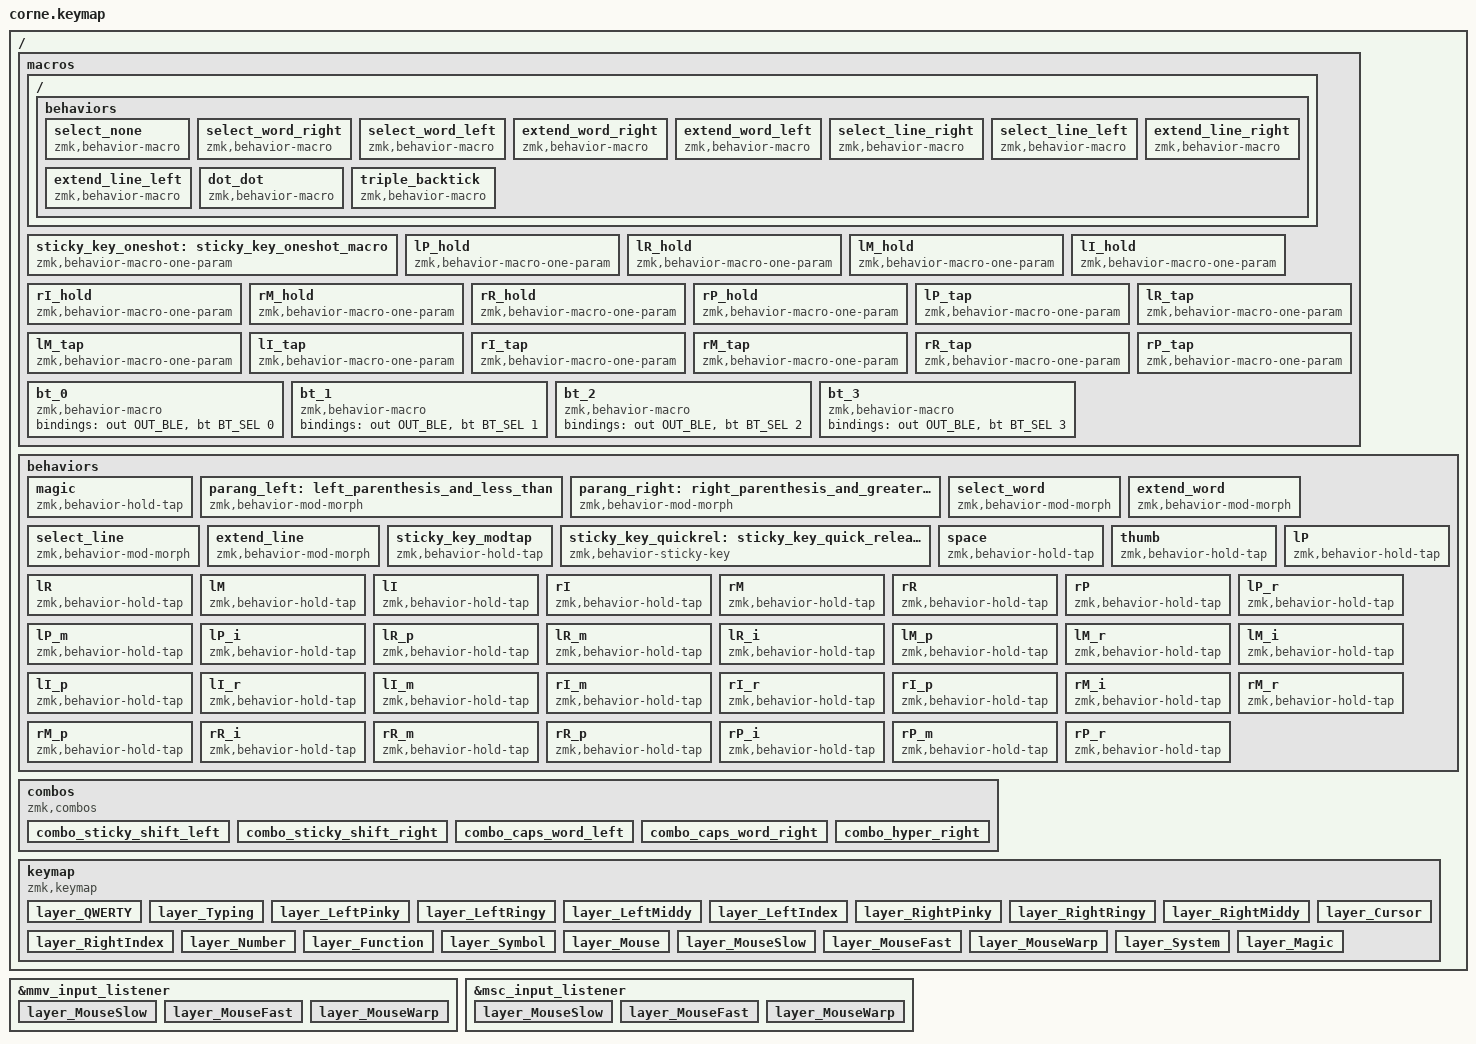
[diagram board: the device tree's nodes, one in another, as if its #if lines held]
/*
 * Copyright (c) 2020 The ZMK Contributors
 * Corne 3x6+3 keymap adapted from MoErgo Go60 with bilateral HRM
 * SPDX-License-Identifier: MIT
 */

#include <behaviors.dtsi>
#include <dt-bindings/zmk/outputs.h>
#include <dt-bindings/zmk/keys.h>
#include <dt-bindings/zmk/bt.h>
#include <dt-bindings/zmk/pointing.h>
#include <input/processors.dtsi>

/* ── Helper macros ── */

/* ZMK_MACRO() comes from <behaviors.dtsi> (app/dts/behaviors/macros.dtsi). */

/* ── sunaku timing constants (keymap.zmk:1724, 3954, 3962, 4091) ── */

#define TAPPING_RESOLUTION  150
#define STICKY_HOLDING_TIME (TAPPING_RESOLUTION + 50)
#define STICKY_1SHOT_DECAY  500
#define SELECT_WORD_DELAY   1

/* ── Operating system ──
 *
 * Verbatim from sunaku's Glorious Engrammer v52 (keymap.zmk:925-967), pinned to
 * macOS. Copied rather than hand-translated so the shortcuts match the Glove80.
 */

#define OPERATING_SYSTEM 'M' // macos

#if OPERATING_SYSTEM == 'M'
  #define _C      LG
  #define _A_TAB  LGUI
  #define _G_TAB  LALT
  #define _REDO   LG(LS(Z))
  #define _POWER  K_POWER
  #define _WORD   LA
  #define _HOME   LG(LEFT)
  #define _END    LG(RIGHT)
  #define _FILES  LG(LA(SPACE))
  #define _GLOBE  GLOBE
#else
  #define _C      LC
  #define _A_TAB  LALT
  #define _G_TAB  LGUI
  #define _REDO   LC(Y)
  #define _POWER  C_POWER
  #define _WORD   LC
  #define _HOME   HOME
  #define _END    END
  #define _FILES  LG(E)
  #define _GLOBE  LGUI
#endif
#define _SLEEP      C_SLEEP
#if OPERATING_SYSTEM == 'M'
  #define _LOCK   _C(LC(Q))
#else
  #define _LOCK   K_LOCK
#endif
#define _UNDO       _C(Z)
#define _CUT        _C(X)
#define _COPY       _C(C)
#define _PASTE      _C(V)
#define _FIND       _C(F)
#define _FIND_NEXT  _C(G)
#define _FIND_PREV  _C(LS(G))

#if OPERATING_SYSTEM == 'M'
  #define _SNAP   LG(LS(N5))  /* macOS screenshot toolbar (Cmd+Shift+5) */
#else
  #define _SNAP   PSCRN
#endif

/* keymap.zmk:4093 -- not a node; expands at the &-site into &kp _C(A) */
#define select_all kp _C(A)

/* ── Layer IDs ──
 *
 * sunaku's 32-layer Glove80 keymap minus what a Corne cannot use: the three alt
 * alpha layouts, Gaming (Glove80 keywell geometry), Emoji/World (reached only
 * from the lost R6), Factory (Glove80-specific), and the macOS toggle layers
 * (macOS is baked into the base instead — see OPERATING_SYSTEM above).
 *
 * 21 of ZMK's 32 slots. Home-row mods relaxed to non-bilateral (see HRM triggers).
 */

#define LAYER_QWERTY 0
#define LAYER_Typing 1
#define LAYER_LeftPinky 2
#define LAYER_LeftRingy 3
#define LAYER_LeftMiddy 4
#define LAYER_LeftIndex 5
#define LAYER_RightPinky 6
#define LAYER_RightRingy 7
#define LAYER_RightMiddy 8
#define LAYER_RightIndex 9
#define LAYER_Cursor 10
#define LAYER_Number 11
#define LAYER_Function 12
#define LAYER_Symbol 13
#define LAYER_Mouse 14
#define LAYER_MouseSlow 15
#define LAYER_MouseFast 16
#define LAYER_MouseWarp 17
#define LAYER_System 18
#define LAYER_Magic 19

/* ── HRM trigger positions (non-bilateral) ── */

/* NON-BILATERAL (full relax): every key position triggers the hold, so home-row
 * mods fire on the SAME hand too -- e.g. one-handed Cmd+T. This drops sunaku's
 * bilateral typing protection by choice; the tap-preferred flavor + the
 * require-prior-idle-ms guards below still gate a mod behind a deliberate ~0.2s
 * hold after a brief pause, which is how you start a shortcut but not how you
 * type mid-word. If fast same-hand typing misfires a mod (Shift on the index,
 * require-prior-idle-ms=25, is likeliest), raise that idle guard. To restore
 * bilateral, set LEFT back to the right-hand positions and RIGHT to the left.
 */
#define LEFT_HRM_TRIGGERS \
    0 1 2 3 4 5 6 7 8 9 10 11 \
    12 13 14 15 16 17 18 19 20 21 22 23 \
    24 25 26 27 28 29 30 31 32 33 34 35 \
    36 37 38 39 40 41

#define RIGHT_HRM_TRIGGERS \
    0 1 2 3 4 5 6 7 8 9 10 11 \
    12 13 14 15 16 17 18 19 20 21 22 23 \
    24 25 26 27 28 29 30 31 32 33 34 35 \
    36 37 38 39 40 41

/* ── System behaviors ── */

/* No &led_strip override: this Corne has no LEDs installed. See build.yaml. */

&mmv_input_listener {
    layer_MouseSlow {
        layers = <LAYER_MouseSlow>;
        input-processors = <&zip_xy_scaler 1 9>;
    };
    layer_MouseFast {
        layers = <LAYER_MouseFast>;
        input-processors = <&zip_xy_scaler 3 1>;
    };
    layer_MouseWarp {
        layers = <LAYER_MouseWarp>;
        input-processors = <&zip_xy_scaler 12 1>;
    };
};

&msc_input_listener {
    layer_MouseSlow {
        layers = <LAYER_MouseSlow>;
        input-processors = <&zip_scroll_scaler 1 9>;
    };
    layer_MouseFast {
        layers = <LAYER_MouseFast>;
        input-processors = <&zip_scroll_scaler 3 1>;
    };
    layer_MouseWarp {
        layers = <LAYER_MouseWarp>;
        input-processors = <&zip_scroll_scaler 12 1>;
    };
};

/* No conditional layers. erickueen's ThumbShift layer (Cursor+Symbol -> shifted
 * alphas) is not part of sunaku's design and is dropped along with its layer.
 */

/* ── Macros ── */

/ {
    macros {

        /* ── Ported from sunaku's Glorious Engrammer v52 ──
         *
         * select/extend family: keymap.zmk:4093-4180. Each is a mod-morph pair so
         * that holding Shift selects/extends leftward instead of rightward. The
         * _WORD/_HOME/_END tokens resolve per OPERATING_SYSTEM (see top of file).
         */

        ZMK_MACRO(select_none,
            wait-ms = <SELECT_WORD_DELAY>;
            tap-ms = <SELECT_WORD_DELAY>;
            bindings = <&kp DOWN &kp UP &kp RIGHT &kp LEFT>;
        )

        ZMK_MACRO(select_word_right,
            wait-ms = <SELECT_WORD_DELAY>;
            tap-ms = <SELECT_WORD_DELAY>;
            bindings = <&kp _WORD(RIGHT) &kp _WORD(LEFT) &kp _WORD(LS(RIGHT))>;
        )
        ZMK_MACRO(select_word_left,
            wait-ms = <SELECT_WORD_DELAY>;
            tap-ms = <SELECT_WORD_DELAY>;
            bindings = <&kp _WORD(LEFT) &kp _WORD(RIGHT) &kp _WORD(LS(LEFT))>;
        )

        ZMK_MACRO(extend_word_right,
            wait-ms = <SELECT_WORD_DELAY>;
            tap-ms = <SELECT_WORD_DELAY>;
            bindings = <&kp _WORD(LS(RIGHT))>;
        )
        ZMK_MACRO(extend_word_left,
            wait-ms = <SELECT_WORD_DELAY>;
            tap-ms = <SELECT_WORD_DELAY>;
            bindings = <&kp _WORD(LS(LEFT))>;
        )

        ZMK_MACRO(select_line_right,
            wait-ms = <SELECT_WORD_DELAY>;
            tap-ms = <SELECT_WORD_DELAY>;
            bindings = <&kp _HOME &kp LS(_END)>;
        )
        ZMK_MACRO(select_line_left,
            wait-ms = <SELECT_WORD_DELAY>;
            tap-ms = <SELECT_WORD_DELAY>;
            bindings = <&kp _END &kp LS(_HOME)>;
        )

        ZMK_MACRO(extend_line_right,
            wait-ms = <SELECT_WORD_DELAY>;
            tap-ms = <SELECT_WORD_DELAY>;
            bindings = <&kp LS(DOWN) &kp LS(_END)>;
        )
        ZMK_MACRO(extend_line_left,
            wait-ms = <SELECT_WORD_DELAY>;
            tap-ms = <SELECT_WORD_DELAY>;
            bindings = <&kp LS(UP) &kp LS(_HOME)>;
        )

        /* keymap.zmk:4014-4024 */
        ZMK_MACRO(dot_dot,
            wait-ms = <0>;
            tap-ms = <0>;
            bindings = <&macro_tap &kp DOT &kp DOT>;
        )
        ZMK_MACRO(triple_backtick,
            wait-ms = <0>;
            tap-ms = <0>;
            bindings = <&macro_tap &kp GRAVE &kp GRAVE &kp GRAVE>;
        )

        /* keymap.zmk:3972-3981 */
        sticky_key_oneshot: sticky_key_oneshot_macro {
            compatible = "zmk,behavior-macro-one-param";
            wait-ms = <0>;
            tap-ms = <0>;
            #binding-cells = <1>;
            bindings
              = <&macro_param_1to1>
              , <&macro_tap &sticky_key_quickrel MACRO_PLACEHOLDER>
              ;
        };









        /* Bilateral HRM hold macros — press modifier + activate layer */

        lP_hold: lP_hold {
            compatible = "zmk,behavior-macro-one-param";
            #binding-cells = <1>;
            tap-ms = <0>; wait-ms = <0>;
            bindings = <&macro_press>
                , <&macro_param_1to1>, <&kp A>
                , <&mo LAYER_LeftPinky>
                , <&macro_pause_for_release>
                , <&macro_release>
                , <&macro_param_1to1>, <&kp A>
                , <&mo LAYER_LeftPinky>;
        };
        lR_hold: lR_hold {
            compatible = "zmk,behavior-macro-one-param";
            #binding-cells = <1>;
            tap-ms = <0>; wait-ms = <0>;
            bindings = <&macro_press>
                , <&macro_param_1to1>, <&kp A>
                , <&mo LAYER_LeftRingy>
                , <&macro_pause_for_release>
                , <&macro_release>
                , <&macro_param_1to1>, <&kp A>
                , <&mo LAYER_LeftRingy>;
        };
        lM_hold: lM_hold {
            compatible = "zmk,behavior-macro-one-param";
            #binding-cells = <1>;
            tap-ms = <0>; wait-ms = <0>;
            bindings = <&macro_press>
                , <&macro_param_1to1>, <&kp A>
                , <&mo LAYER_LeftMiddy>
                , <&macro_pause_for_release>
                , <&macro_release>
                , <&macro_param_1to1>, <&kp A>
                , <&mo LAYER_LeftMiddy>;
        };
        lI_hold: lI_hold {
            compatible = "zmk,behavior-macro-one-param";
            #binding-cells = <1>;
            tap-ms = <0>; wait-ms = <0>;
            bindings = <&macro_press>
                , <&macro_param_1to1>, <&kp A>
                , <&mo LAYER_LeftIndex>
                , <&macro_pause_for_release>
                , <&macro_release>
                , <&macro_param_1to1>, <&kp A>
                , <&mo LAYER_LeftIndex>;
        };
        rI_hold: rI_hold {
            compatible = "zmk,behavior-macro-one-param";
            #binding-cells = <1>;
            tap-ms = <0>; wait-ms = <0>;
            bindings = <&macro_press>
                , <&macro_param_1to1>, <&kp A>
                , <&mo LAYER_RightIndex>
                , <&macro_pause_for_release>
                , <&macro_release>
                , <&macro_param_1to1>, <&kp A>
                , <&mo LAYER_RightIndex>;
        };
        rM_hold: rM_hold {
            compatible = "zmk,behavior-macro-one-param";
            #binding-cells = <1>;
            tap-ms = <0>; wait-ms = <0>;
            bindings = <&macro_press>
                , <&macro_param_1to1>, <&kp A>
                , <&mo LAYER_RightMiddy>
                , <&macro_pause_for_release>
                , <&macro_release>
                , <&macro_param_1to1>, <&kp A>
                , <&mo LAYER_RightMiddy>;
        };
        rR_hold: rR_hold {
            compatible = "zmk,behavior-macro-one-param";
            #binding-cells = <1>;
            tap-ms = <0>; wait-ms = <0>;
            bindings = <&macro_press>
                , <&macro_param_1to1>, <&kp A>
                , <&mo LAYER_RightRingy>
                , <&macro_pause_for_release>
                , <&macro_release>
                , <&macro_param_1to1>, <&kp A>
                , <&mo LAYER_RightRingy>;
        };
        rP_hold: rP_hold {
            compatible = "zmk,behavior-macro-one-param";
            #binding-cells = <1>;
            tap-ms = <0>; wait-ms = <0>;
            bindings = <&macro_press>
                , <&macro_param_1to1>, <&kp A>
                , <&mo LAYER_RightPinky>
                , <&macro_pause_for_release>
                , <&macro_release>
                , <&macro_param_1to1>, <&kp A>
                , <&mo LAYER_RightPinky>;
        };

        /* Bilateral HRM tap macros — release all mods, tap held key, tap param key */

        lP_tap: lP_tap {
            compatible = "zmk,behavior-macro-one-param";
            #binding-cells = <1>;
            tap-ms = <0>; wait-ms = <0>;
            bindings = <&macro_release>
                , <&kp LSHFT>, <&kp RSHFT>, <&kp LALT>, <&kp RALT>
                , <&kp LCTRL>, <&kp RCTRL>, <&kp LGUI>, <&kp RGUI>
                , <&macro_tap>, <&kp A>
                , <&macro_tap>, <&macro_param_1to1>, <&kp A>;
        };
        lR_tap: lR_tap {
            compatible = "zmk,behavior-macro-one-param";
            #binding-cells = <1>;
            tap-ms = <0>; wait-ms = <0>;
            bindings = <&macro_release>
                , <&kp LSHFT>, <&kp RSHFT>, <&kp LALT>, <&kp RALT>
                , <&kp LCTRL>, <&kp RCTRL>, <&kp LGUI>, <&kp RGUI>
                , <&macro_tap>, <&kp S>
                , <&macro_tap>, <&macro_param_1to1>, <&kp A>;
        };
        lM_tap: lM_tap {
            compatible = "zmk,behavior-macro-one-param";
            #binding-cells = <1>;
            tap-ms = <0>; wait-ms = <0>;
            bindings = <&macro_release>
                , <&kp LSHFT>, <&kp RSHFT>, <&kp LALT>, <&kp RALT>
                , <&kp LCTRL>, <&kp RCTRL>, <&kp LGUI>, <&kp RGUI>
                , <&macro_tap>, <&kp D>
                , <&macro_tap>, <&macro_param_1to1>, <&kp A>;
        };
        lI_tap: lI_tap {
            compatible = "zmk,behavior-macro-one-param";
            #binding-cells = <1>;
            tap-ms = <0>; wait-ms = <0>;
            bindings = <&macro_release>
                , <&kp LSHFT>, <&kp RSHFT>, <&kp LALT>, <&kp RALT>
                , <&kp LCTRL>, <&kp RCTRL>, <&kp LGUI>, <&kp RGUI>
                , <&macro_tap>, <&kp F>
                , <&macro_tap>, <&macro_param_1to1>, <&kp A>;
        };
        rI_tap: rI_tap {
            compatible = "zmk,behavior-macro-one-param";
            #binding-cells = <1>;
            tap-ms = <0>; wait-ms = <0>;
            bindings = <&macro_release>
                , <&kp LSHFT>, <&kp RSHFT>, <&kp LALT>, <&kp RALT>
                , <&kp LCTRL>, <&kp RCTRL>, <&kp LGUI>, <&kp RGUI>
                , <&macro_tap>, <&kp J>
                , <&macro_tap>, <&macro_param_1to1>, <&kp A>;
        };
        rM_tap: rM_tap {
            compatible = "zmk,behavior-macro-one-param";
            #binding-cells = <1>;
            tap-ms = <0>; wait-ms = <0>;
            bindings = <&macro_release>
                , <&kp LSHFT>, <&kp RSHFT>, <&kp LALT>, <&kp RALT>
                , <&kp LCTRL>, <&kp RCTRL>, <&kp LGUI>, <&kp RGUI>
                , <&macro_tap>, <&kp K>
                , <&macro_tap>, <&macro_param_1to1>, <&kp A>;
        };
        rR_tap: rR_tap {
            compatible = "zmk,behavior-macro-one-param";
            #binding-cells = <1>;
            tap-ms = <0>; wait-ms = <0>;
            bindings = <&macro_release>
                , <&kp LSHFT>, <&kp RSHFT>, <&kp LALT>, <&kp RALT>
                , <&kp LCTRL>, <&kp RCTRL>, <&kp LGUI>, <&kp RGUI>
                , <&macro_tap>, <&kp L>
                , <&macro_tap>, <&macro_param_1to1>, <&kp A>;
        };
        rP_tap: rP_tap {
            compatible = "zmk,behavior-macro-one-param";
            #binding-cells = <1>;
            tap-ms = <0>; wait-ms = <0>;
            bindings = <&macro_release>
                , <&kp LSHFT>, <&kp RSHFT>, <&kp LALT>, <&kp RALT>
                , <&kp LCTRL>, <&kp RCTRL>, <&kp LGUI>, <&kp RGUI>
                , <&macro_tap>, <&kp SEMI>
                , <&macro_tap>, <&macro_param_1to1>, <&kp A>;
        };

        /* Bluetooth macros */

        bt_0: bt_0 { compatible = "zmk,behavior-macro"; #binding-cells = <0>;
            bindings = <&out OUT_BLE>, <&bt BT_SEL 0>; };
        bt_1: bt_1 { compatible = "zmk,behavior-macro"; #binding-cells = <0>;
            bindings = <&out OUT_BLE>, <&bt BT_SEL 1>; };
        bt_2: bt_2 { compatible = "zmk,behavior-macro"; #binding-cells = <0>;
            bindings = <&out OUT_BLE>, <&bt BT_SEL 2>; };
        bt_3: bt_3 { compatible = "zmk,behavior-macro"; #binding-cells = <0>;
            bindings = <&out OUT_BLE>, <&bt BT_SEL 3>; };


    };
};

/* ── Behaviors ── */

/ {
    behaviors {

        /* sunaku taps Magic to flash RGB battery/BT status. With no LEDs there is
         * nothing to show, so the tap is a no-op and only the hold is used.
         */
        magic: magic {
            compatible = "zmk,behavior-hold-tap";
            #binding-cells = <2>;
            flavor = "tap-preferred";
            tapping-term-ms = <200>;
            bindings = <&mo>, <&none>;
        };

        /* ── Ported from sunaku's Glorious Engrammer v52 ── */

        /* keymap.zmk:3926-3941. Shift morphs ( ) into < > */
        parang_left: left_parenthesis_and_less_than {
            compatible = "zmk,behavior-mod-morph";
            #binding-cells = <0>;
            bindings = <&kp LPAR>, <&kp LT>;
            mods = <(MOD_LSFT|MOD_RSFT)>;
        };
        parang_right: right_parenthesis_and_greater_than {
            compatible = "zmk,behavior-mod-morph";
            #binding-cells = <0>;
            bindings = <&kp RPAR>, <&kp GT>;
            mods = <(MOD_LSFT|MOD_RSFT)>;
        };

        /* keymap.zmk:4105-4180. Shift selects/extends leftward. */
        select_word: select_word {
            compatible = "zmk,behavior-mod-morph";
            #binding-cells = <0>;
            bindings = <&select_word_right>, <&select_word_left>;
            mods = <(MOD_LSFT|MOD_RSFT)>;
        };
        extend_word: extend_word {
            compatible = "zmk,behavior-mod-morph";
            #binding-cells = <0>;
            bindings = <&extend_word_right>, <&extend_word_left>;
            mods = <(MOD_LSFT|MOD_RSFT)>;
        };
        select_line: select_line {
            compatible = "zmk,behavior-mod-morph";
            #binding-cells = <0>;
            bindings = <&select_line_right>, <&select_line_left>;
            mods = <(MOD_LSFT|MOD_RSFT)>;
        };
        extend_line: extend_line {
            compatible = "zmk,behavior-mod-morph";
            #binding-cells = <0>;
            bindings = <&extend_line_right>, <&extend_line_left>;
            mods = <(MOD_LSFT|MOD_RSFT)>;
        };

        /* keymap.zmk:3965-3989. Hold = plain mod; tap = one-shot sticky mod. */
        sticky_key_modtap: sticky_key_modtap {
            compatible = "zmk,behavior-hold-tap";
            flavor = "tap-preferred";
            tapping-term-ms = <STICKY_HOLDING_TIME>;
            #binding-cells = <2>;
            bindings = <&kp>, <&sticky_key_oneshot>;
        };
        sticky_key_quickrel: sticky_key_quick_release {
            compatible = "zmk,behavior-sticky-key";
            #binding-cells = <1>;
            bindings = <&kp>;
            release-after-ms = <STICKY_1SHOT_DECAY>;
            quick-release;
            ignore-modifiers;
        };


        space: space {
            compatible = "zmk,behavior-hold-tap";
            #binding-cells = <2>;
            tapping-term-ms = <200>;
            bindings = <&mo>, <&kp>;
            flavor = "balanced";
            quick-tap-ms = <150>;
        };

        thumb: thumb {
            compatible = "zmk,behavior-hold-tap";
            #binding-cells = <2>;
            tapping-term-ms = <200>;
            bindings = <&mo>, <&kp>;
            flavor = "balanced";
            quick-tap-ms = <300>;
        };



        /* ── Left hand main HRM hold-taps ── */

        lP: lP { compatible = "zmk,behavior-hold-tap"; #binding-cells = <2>;
            tapping-term-ms = <280>; bindings = <&lP_hold>, <&kp>;
            flavor = "tap-preferred"; quick-tap-ms = <300>;
            require-prior-idle-ms = <150>;
            hold-trigger-key-positions = <LEFT_HRM_TRIGGERS>;
            hold-trigger-on-release; };
        lR: lR { compatible = "zmk,behavior-hold-tap"; #binding-cells = <2>;
            tapping-term-ms = <240>; bindings = <&lR_hold>, <&kp>;
            flavor = "tap-preferred"; quick-tap-ms = <300>;
            require-prior-idle-ms = <150>;
            hold-trigger-key-positions = <LEFT_HRM_TRIGGERS>;
            hold-trigger-on-release; };
        lM: lM { compatible = "zmk,behavior-hold-tap"; #binding-cells = <2>;
            tapping-term-ms = <210>; bindings = <&lM_hold>, <&kp>;
            flavor = "tap-preferred"; quick-tap-ms = <300>;
            require-prior-idle-ms = <150>;
            hold-trigger-key-positions = <LEFT_HRM_TRIGGERS>;
            hold-trigger-on-release; };
        lI: lI { compatible = "zmk,behavior-hold-tap"; #binding-cells = <2>;
            tapping-term-ms = <190>; bindings = <&lI_hold>, <&kp>;
            flavor = "tap-preferred"; quick-tap-ms = <300>;
            require-prior-idle-ms = <25>;
            hold-trigger-key-positions = <LEFT_HRM_TRIGGERS>;
            hold-trigger-on-release; };

        /* ── Right hand main HRM hold-taps ── */

        rI: rI { compatible = "zmk,behavior-hold-tap"; #binding-cells = <2>;
            tapping-term-ms = <190>; bindings = <&rI_hold>, <&kp>;
            flavor = "tap-preferred"; quick-tap-ms = <300>;
            require-prior-idle-ms = <25>;
            hold-trigger-key-positions = <RIGHT_HRM_TRIGGERS>;
            hold-trigger-on-release; };
        rM: rM { compatible = "zmk,behavior-hold-tap"; #binding-cells = <2>;
            tapping-term-ms = <210>; bindings = <&rM_hold>, <&kp>;
            flavor = "tap-preferred"; quick-tap-ms = <300>;
            require-prior-idle-ms = <150>;
            hold-trigger-key-positions = <RIGHT_HRM_TRIGGERS>;
            hold-trigger-on-release; };
        rR: rR { compatible = "zmk,behavior-hold-tap"; #binding-cells = <2>;
            tapping-term-ms = <240>; bindings = <&rR_hold>, <&kp>;
            flavor = "tap-preferred"; quick-tap-ms = <300>;
            require-prior-idle-ms = <150>;
            hold-trigger-key-positions = <RIGHT_HRM_TRIGGERS>;
            hold-trigger-on-release; };
        rP: rP { compatible = "zmk,behavior-hold-tap"; #binding-cells = <2>;
            tapping-term-ms = <260>; bindings = <&rP_hold>, <&kp>;
            flavor = "tap-preferred"; quick-tap-ms = <300>;
            require-prior-idle-ms = <150>;
            hold-trigger-key-positions = <RIGHT_HRM_TRIGGERS>;
            hold-trigger-on-release; };

        /* ── Left pinky bilateral cross-variants ── */

        lP_r: lP_r { compatible = "zmk,behavior-hold-tap"; #binding-cells = <2>;
            tapping-term-ms = <280>; bindings = <&kp>, <&lP_tap>;
            flavor = "tap-preferred"; quick-tap-ms = <300>;
            require-prior-idle-ms = <150>;
            hold-trigger-key-positions = <LEFT_HRM_TRIGGERS>;
            hold-trigger-on-release; };
        lP_m: lP_m { compatible = "zmk,behavior-hold-tap"; #binding-cells = <2>;
            tapping-term-ms = <280>; bindings = <&kp>, <&lP_tap>;
            flavor = "tap-preferred"; quick-tap-ms = <300>;
            require-prior-idle-ms = <150>;
            hold-trigger-key-positions = <LEFT_HRM_TRIGGERS>;
            hold-trigger-on-release; };
        lP_i: lP_i { compatible = "zmk,behavior-hold-tap"; #binding-cells = <2>;
            tapping-term-ms = <280>; bindings = <&kp>, <&lP_tap>;
            flavor = "tap-preferred"; quick-tap-ms = <300>;
            require-prior-idle-ms = <150>;
            hold-trigger-key-positions = <LEFT_HRM_TRIGGERS>;
            hold-trigger-on-release; };

        /* ── Left ring bilateral cross-variants ── */

        lR_p: lR_p { compatible = "zmk,behavior-hold-tap"; #binding-cells = <2>;
            tapping-term-ms = <240>; bindings = <&kp>, <&lR_tap>;
            flavor = "tap-preferred"; quick-tap-ms = <300>;
            require-prior-idle-ms = <150>;
            hold-trigger-key-positions = <LEFT_HRM_TRIGGERS>;
            hold-trigger-on-release; };
        lR_m: lR_m { compatible = "zmk,behavior-hold-tap"; #binding-cells = <2>;
            tapping-term-ms = <240>; bindings = <&kp>, <&lR_tap>;
            flavor = "tap-preferred"; quick-tap-ms = <300>;
            require-prior-idle-ms = <150>;
            hold-trigger-key-positions = <LEFT_HRM_TRIGGERS>;
            hold-trigger-on-release; };
        lR_i: lR_i { compatible = "zmk,behavior-hold-tap"; #binding-cells = <2>;
            tapping-term-ms = <240>; bindings = <&kp>, <&lR_tap>;
            flavor = "tap-preferred"; quick-tap-ms = <300>;
            require-prior-idle-ms = <100>;
            hold-trigger-key-positions = <LEFT_HRM_TRIGGERS>;
            hold-trigger-on-release; };

        /* ── Left middle bilateral cross-variants ── */

        lM_p: lM_p { compatible = "zmk,behavior-hold-tap"; #binding-cells = <2>;
            tapping-term-ms = <210>; bindings = <&kp>, <&lM_tap>;
            flavor = "tap-preferred"; quick-tap-ms = <300>;
            require-prior-idle-ms = <150>;
            hold-trigger-key-positions = <LEFT_HRM_TRIGGERS>;
            hold-trigger-on-release; };
        lM_r: lM_r { compatible = "zmk,behavior-hold-tap"; #binding-cells = <2>;
            tapping-term-ms = <210>; bindings = <&kp>, <&lM_tap>;
            flavor = "tap-preferred"; quick-tap-ms = <300>;
            require-prior-idle-ms = <150>;
            hold-trigger-key-positions = <LEFT_HRM_TRIGGERS>;
            hold-trigger-on-release; };
        lM_i: lM_i { compatible = "zmk,behavior-hold-tap"; #binding-cells = <2>;
            tapping-term-ms = <210>; bindings = <&kp>, <&lM_tap>;
            flavor = "tap-preferred"; quick-tap-ms = <300>;
            require-prior-idle-ms = <150>;
            hold-trigger-key-positions = <LEFT_HRM_TRIGGERS>;
            hold-trigger-on-release; };

        /* ── Left index bilateral cross-variants ── */

        lI_p: lI_p { compatible = "zmk,behavior-hold-tap"; #binding-cells = <2>;
            tapping-term-ms = <190>; bindings = <&kp>, <&lI_tap>;
            flavor = "tap-preferred"; quick-tap-ms = <300>;
            require-prior-idle-ms = <25>;
            hold-trigger-key-positions = <LEFT_HRM_TRIGGERS>;
            hold-trigger-on-release; };
        lI_r: lI_r { compatible = "zmk,behavior-hold-tap"; #binding-cells = <2>;
            tapping-term-ms = <190>; bindings = <&kp>, <&lI_tap>;
            flavor = "tap-preferred"; quick-tap-ms = <300>;
            require-prior-idle-ms = <25>;
            hold-trigger-key-positions = <LEFT_HRM_TRIGGERS>;
            hold-trigger-on-release; };
        lI_m: lI_m { compatible = "zmk,behavior-hold-tap"; #binding-cells = <2>;
            tapping-term-ms = <190>; bindings = <&kp>, <&lI_tap>;
            flavor = "tap-preferred"; quick-tap-ms = <300>;
            require-prior-idle-ms = <25>;
            hold-trigger-key-positions = <LEFT_HRM_TRIGGERS>;
            hold-trigger-on-release; };

        /* ── Right index bilateral cross-variants ── */

        rI_m: rI_m { compatible = "zmk,behavior-hold-tap"; #binding-cells = <2>;
            tapping-term-ms = <190>; bindings = <&kp>, <&rI_tap>;
            flavor = "tap-preferred"; quick-tap-ms = <300>;
            require-prior-idle-ms = <25>;
            hold-trigger-key-positions = <RIGHT_HRM_TRIGGERS>;
            hold-trigger-on-release; };
        rI_r: rI_r { compatible = "zmk,behavior-hold-tap"; #binding-cells = <2>;
            tapping-term-ms = <190>; bindings = <&kp>, <&rI_tap>;
            flavor = "tap-preferred"; quick-tap-ms = <300>;
            require-prior-idle-ms = <25>;
            hold-trigger-key-positions = <RIGHT_HRM_TRIGGERS>;
            hold-trigger-on-release; };
        rI_p: rI_p { compatible = "zmk,behavior-hold-tap"; #binding-cells = <2>;
            tapping-term-ms = <190>; bindings = <&kp>, <&rI_tap>;
            flavor = "tap-preferred"; quick-tap-ms = <300>;
            require-prior-idle-ms = <25>;
            hold-trigger-key-positions = <RIGHT_HRM_TRIGGERS>;
            hold-trigger-on-release; };

        /* ── Right middle bilateral cross-variants ── */

        rM_i: rM_i { compatible = "zmk,behavior-hold-tap"; #binding-cells = <2>;
            tapping-term-ms = <210>; bindings = <&kp>, <&rM_tap>;
            flavor = "tap-preferred"; quick-tap-ms = <300>;
            require-prior-idle-ms = <150>;
            hold-trigger-key-positions = <RIGHT_HRM_TRIGGERS>;
            hold-trigger-on-release; };
        rM_r: rM_r { compatible = "zmk,behavior-hold-tap"; #binding-cells = <2>;
            tapping-term-ms = <210>; bindings = <&kp>, <&rM_tap>;
            flavor = "tap-preferred"; quick-tap-ms = <300>;
            require-prior-idle-ms = <150>;
            hold-trigger-key-positions = <RIGHT_HRM_TRIGGERS>;
            hold-trigger-on-release; };
        rM_p: rM_p { compatible = "zmk,behavior-hold-tap"; #binding-cells = <2>;
            tapping-term-ms = <210>; bindings = <&kp>, <&rM_tap>;
            flavor = "tap-preferred"; quick-tap-ms = <300>;
            require-prior-idle-ms = <150>;
            hold-trigger-key-positions = <RIGHT_HRM_TRIGGERS>;
            hold-trigger-on-release; };

        /* ── Right ring bilateral cross-variants ── */

        rR_i: rR_i { compatible = "zmk,behavior-hold-tap"; #binding-cells = <2>;
            tapping-term-ms = <240>; bindings = <&kp>, <&rR_tap>;
            flavor = "tap-preferred"; quick-tap-ms = <300>;
            require-prior-idle-ms = <150>;
            hold-trigger-key-positions = <RIGHT_HRM_TRIGGERS>;
            hold-trigger-on-release; };
        rR_m: rR_m { compatible = "zmk,behavior-hold-tap"; #binding-cells = <2>;
            tapping-term-ms = <240>; bindings = <&kp>, <&rR_tap>;
            flavor = "tap-preferred"; quick-tap-ms = <300>;
            require-prior-idle-ms = <150>;
            hold-trigger-key-positions = <RIGHT_HRM_TRIGGERS>;
            hold-trigger-on-release; };
        rR_p: rR_p { compatible = "zmk,behavior-hold-tap"; #binding-cells = <2>;
            tapping-term-ms = <240>; bindings = <&kp>, <&rR_tap>;
            flavor = "tap-preferred"; quick-tap-ms = <300>;
            require-prior-idle-ms = <150>;
            hold-trigger-key-positions = <RIGHT_HRM_TRIGGERS>;
            hold-trigger-on-release; };

        /* ── Right pinky bilateral cross-variants ── */

        rP_i: rP_i { compatible = "zmk,behavior-hold-tap"; #binding-cells = <2>;
            tapping-term-ms = <260>; bindings = <&kp>, <&rP_tap>;
            flavor = "tap-preferred"; quick-tap-ms = <300>;
            require-prior-idle-ms = <150>;
            hold-trigger-key-positions = <RIGHT_HRM_TRIGGERS>;
            hold-trigger-on-release; };
        rP_m: rP_m { compatible = "zmk,behavior-hold-tap"; #binding-cells = <2>;
            tapping-term-ms = <260>; bindings = <&kp>, <&rP_tap>;
            flavor = "tap-preferred"; quick-tap-ms = <300>;
            require-prior-idle-ms = <150>;
            hold-trigger-key-positions = <RIGHT_HRM_TRIGGERS>;
            hold-trigger-on-release; };
        rP_r: rP_r { compatible = "zmk,behavior-hold-tap"; #binding-cells = <2>;
            tapping-term-ms = <260>; bindings = <&kp>, <&rP_tap>;
            flavor = "tap-preferred"; quick-tap-ms = <300>;
            require-prior-idle-ms = <150>;
            hold-trigger-key-positions = <RIGHT_HRM_TRIGGERS>;
            hold-trigger-on-release; };
    };
};

/* ── Combos ── */

/ {
    combos {
        compatible = "zmk,combos";

        /* sunaku's thumb combos, v52 keymap.zmk:1478-1677.
         *
         * With 3 thumbs per hand only three pairs exist -- T1+T4, T1+T5, T4+T5 --
         * and all three are spoken for. The 16 combos that needed T2/T3/T6 are
         * dropped (Ctrl-Tab / Cmd-Tab switchers, sticky AltGr, sticky Globe,
         * CapsLock -- which survives on the System layer anyway).
         *
         * Thumb positions: LH T1=36 T5=37 T4=38 | RH T4=39 T5=40 T1=41
         */

        combo_sticky_shift_left { timeout-ms = <50>; key-positions = <36 37>;
            bindings = <&sticky_key_modtap LSFT LSFT>;
            layers = <LAYER_QWERTY LAYER_Typing>; };

        combo_sticky_shift_right { timeout-ms = <50>; key-positions = <40 41>;
            bindings = <&sticky_key_modtap RSFT RSFT>;
            layers = <LAYER_QWERTY LAYER_Typing>; };

        combo_caps_word_left { timeout-ms = <50>; key-positions = <37 38>;
            bindings = <&caps_word>;
            layers = <LAYER_QWERTY LAYER_Typing>; };

        combo_caps_word_right { timeout-ms = <50>; key-positions = <39 40>;
            bindings = <&caps_word>;
            layers = <LAYER_QWERTY LAYER_Typing>; };

        combo_hyper_right { timeout-ms = <50>; key-positions = <39 41>;
            bindings = <&kp LG(LA(LC(LSHFT)))>;
            layers = <LAYER_QWERTY LAYER_Typing>; };

    };
};

/* ── Keymap ── */

/ {
    keymap {
        compatible = "zmk,keymap";

        /* Corne 42-key position map (left | right):
         *
         *    0  1  2  3  4  5  |  6  7  8  9 10 11
         *   12 13 14 15 16 17  | 18 19 20 21 22 23
         *   24 25 26 27 28 29  | 30 31 32 33 34 35
         *         36 37 38     | 39 40 41
         *
         * Glove80 rows R3/R4/R5 map 1:1 onto rows 1/2/3. R1, R2 and R6 have no
         * home here; what they carried is rehomed or dropped (see README).
         *
         * Thumbs -- sunaku's QWERTY build uses exactly T1/T4/T5 per hand, which is
         * exactly what a Corne has. Assigned by frequency onto Corne ergonomics:
         *
         *   36 = L outer  Bspc  -> Cursor       39 = R inner  Enter -> System
         *   37 = L mid    Del   -> Number       40 = R mid    Tab   -> Mouse
         *   38 = L inner  Esc   -> Function     41 = R outer  Space -> Symbol
         */

        layer_QWERTY {
            display-name = "BASE";
            bindings = <
   &kp F12               &kp Q        &kp W        &kp E        &kp R  &kp T        &kp Y        &kp U        &kp I       &kp O           &kp P                       &kp MINUS
   &kp EQUAL       &lP LCTRL A  &lR LALT S   &lM LGUI D   &lI LSHFT F  &kp G        &kp H  &rI RSHFT J  &rM RGUI K  &rR LALT L  &rP RCTRL SEMI                         &kp SQT
   &magic LAYER_Magic 0  &kp Z        &kp X        &kp C        &kp V  &kp B        &kp N        &kp M    &kp COMMA     &kp DOT        &kp FSLH  &sticky_key_modtap RSFT RSFT
                          &thumb LAYER_Function ESC  &thumb LAYER_Cursor BSPC  &thumb LAYER_Number DEL        &thumb LAYER_Mouse TAB  &space LAYER_Symbol SPACE  &thumb LAYER_System ENTER
            >;
        };

        /* Turns the hold-taps back into plain keys for fast typing / auto-repeat. */
        layer_Typing {
            display-name = "TYPE";
            bindings = <
   &trans  &trans  &trans  &trans  &trans  &trans     &trans  &trans  &trans  &trans     &trans  &trans
   &trans   &kp A   &kp S   &kp D   &kp F  &trans     &trans   &kp J   &kp K   &kp L   &kp SEMI  &trans
   &trans  &trans  &trans  &trans  &trans  &trans     &trans  &trans  &trans  &trans     &trans  &trans
                     &kp ESC  &kp BSPC  &kp DEL        &kp TAB  &kp SPACE  &kp ENTER
            >;
        };

        /* ── Bilateral enforcement (8 layers) ──
         *
         * Each HRM hold also activates its finger's layer, where every same-hand
         * key becomes a _tap variant that releases all mods and types the plain
         * key -- so same-hand chords self-cancel and only cross-hand chords apply
         * the modifier. Opposite-hand keys stay &trans.
         */

        layer_LeftPinky {
            display-name = "LP";
            bindings = <
   &trans  &lP_tap Q      &lP_tap W     &lP_tap E      &lP_tap R  &lP_tap T  &trans  &trans  &trans  &trans    &trans  &trans
   &lP_tap EQUAL      &none  &lP_r LALT S  &lP_m LGUI D  &lP_i LSHFT F  &lP_tap G  &trans   &kp J   &kp K   &kp L  &kp SEMI  &trans
   &trans  &lP_tap Z      &lP_tap X     &lP_tap C      &lP_tap V  &lP_tap B  &trans  &trans  &trans  &trans    &trans  &trans
                    &mo LAYER_Function  &mo LAYER_Cursor  &mo LAYER_Number        &trans  &trans  &trans
            >;
        };

        layer_LeftRingy {
            display-name = "LR";
            bindings = <
   &trans      &lR_tap Q  &lR_tap W     &lR_tap E      &lR_tap R  &lR_tap T  &trans  &trans  &trans  &trans    &trans  &trans
   &lR_tap EQUAL  &lR_p LCTRL A      &none  &lR_m LGUI D  &lR_i LSHFT F  &lR_tap G  &trans   &kp J   &kp K   &kp L  &kp SEMI  &trans
   &trans      &lR_tap Z  &lR_tap X     &lR_tap C      &lR_tap V  &lR_tap B  &trans  &trans  &trans  &trans    &trans  &trans
                    &mo LAYER_Function  &mo LAYER_Cursor  &mo LAYER_Number        &trans  &trans  &trans
            >;
        };

        layer_LeftMiddy {
            display-name = "LM";
            bindings = <
   &trans      &lM_tap Q     &lM_tap W  &lM_tap E      &lM_tap R  &lM_tap T  &trans  &trans  &trans  &trans    &trans  &trans
   &lM_tap EQUAL  &lM_p LCTRL A  &lM_r LALT S      &none  &lM_i LSHFT F  &lM_tap G  &trans   &kp J   &kp K   &kp L  &kp SEMI  &trans
   &trans      &lM_tap Z     &lM_tap X  &lM_tap C      &lM_tap V  &lM_tap B  &trans  &trans  &trans  &trans    &trans  &trans
                    &mo LAYER_Function  &mo LAYER_Cursor  &mo LAYER_Number        &trans  &trans  &trans
            >;
        };

        layer_LeftIndex {
            display-name = "LI";
            bindings = <
   &trans      &lI_tap Q     &lI_tap W     &lI_tap E  &lI_tap R  &lI_tap T  &trans  &trans  &trans  &trans    &trans  &trans
   &lI_tap EQUAL  &lI_p LCTRL A  &lI_r LALT S  &lI_m LGUI D      &none  &lI_tap G  &trans   &kp J   &kp K   &kp L  &kp SEMI  &trans
   &trans      &lI_tap Z     &lI_tap X     &lI_tap C  &lI_tap V  &lI_tap B  &trans  &trans  &trans  &trans    &trans  &trans
                    &mo LAYER_Function  &mo LAYER_Cursor  &mo LAYER_Number        &trans  &trans  &trans
            >;
        };

        layer_RightPinky {
            display-name = "RP";
            bindings = <
   &trans  &trans  &trans  &trans  &trans  &trans      &rP_tap Y      &rP_tap U     &rP_tap I      &rP_tap O          &rP_tap P  &rP_tap MINUS
   &trans   &kp A   &kp S   &kp D   &kp F  &trans      &rP_tap H  &rP_i RSHFT J  &rP_m RGUI K  &rP_r LALT L              &none    &rP_tap SQT
   &trans  &trans  &trans  &trans  &trans  &trans      &rP_tap N      &rP_tap M  &rP_tap COMMA    &rP_tap DOT      &rP_tap FSLH         &trans
                    &trans  &trans  &trans        &mo LAYER_Mouse  &mo LAYER_Symbol  &mo LAYER_System
            >;
        };

        layer_RightRingy {
            display-name = "RR";
            bindings = <
   &trans  &trans  &trans  &trans  &trans  &trans      &rR_tap Y      &rR_tap U     &rR_tap I         &rR_tap O          &rR_tap P  &rR_tap MINUS
   &trans   &kp A   &kp S   &kp D   &kp F  &trans      &rR_tap H  &rR_i RSHFT J  &rR_m RGUI K             &none  &rR_p RCTRL SEMI    &rR_tap SQT
   &trans  &trans  &trans  &trans  &trans  &trans      &rR_tap N      &rR_tap M  &rR_tap COMMA       &rR_tap DOT      &rR_tap FSLH         &trans
                    &trans  &trans  &trans        &mo LAYER_Mouse  &mo LAYER_Symbol  &mo LAYER_System
            >;
        };

        layer_RightMiddy {
            display-name = "RM";
            bindings = <
   &trans  &trans  &trans  &trans  &trans  &trans      &rM_tap Y      &rM_tap U        &rM_tap I     &rM_tap O          &rM_tap P  &rM_tap MINUS
   &trans   &kp A   &kp S   &kp D   &kp F  &trans      &rM_tap H  &rM_i RSHFT J            &none  &rM_r LALT L  &rM_p RCTRL SEMI    &rM_tap SQT
   &trans  &trans  &trans  &trans  &trans  &trans      &rM_tap N      &rM_tap M    &rM_tap COMMA   &rM_tap DOT      &rM_tap FSLH         &trans
                    &trans  &trans  &trans        &mo LAYER_Mouse  &mo LAYER_Symbol  &mo LAYER_System
            >;
        };

        layer_RightIndex {
            display-name = "RI";
            bindings = <
   &trans  &trans  &trans  &trans  &trans  &trans      &rI_tap Y      &rI_tap U     &rI_tap I     &rI_tap O          &rI_tap P  &rI_tap MINUS
   &trans   &kp A   &kp S   &kp D   &kp F  &trans      &rI_tap H          &none  &rI_m RGUI K  &rI_r LALT L  &rI_p RCTRL SEMI    &rI_tap SQT
   &trans  &trans  &trans  &trans  &trans  &trans      &rI_tap N      &rI_tap M  &rI_tap COMMA   &rI_tap DOT      &rI_tap FSLH         &trans
                    &trans  &trans  &trans        &mo LAYER_Mouse  &mo LAYER_Symbol  &mo LAYER_System
            >;
        };

        /* ── Thumb layers ── */

        layer_Cursor {
            display-name = "CURS";
            bindings = <
   &none  &kp RET  &kp SPACE  &kp TAB  &kp BSPC  &kp _CUT     &kp _CUT  &kp _HOME  &kp PG_UP  &kp PG_DN  &kp _END  &none
   &sk LSHFT  &kp LCTRL  &kp LALT  &kp LGUI  &kp LSHFT  &kp _COPY     &kp _COPY  &kp LEFT  &kp UP  &kp DOWN  &kp RIGHT  &sk LSHFT
   &kp _C(L)  &kp _UNDO  &kp _REDO  &kp _FIND_PREV  &kp _FIND_NEXT  &kp _PASTE     &kp _PASTE  &kp _FIND  &kp _FIND_PREV  &kp _FIND_NEXT  &kp LG(LA(F))  &kp _C(L)
                     &none  &tog LAYER_Cursor  &none     &select_line  &select_word  &select_all
            >;
        };

        /* Hex A-D recovered onto the Ret/Space/Tab/Bspc mirror block, which is
         * redundant here (all four are on the thumbs). With E and F already on
         * row 3 and X on row 2, the full hex set survives.
         */
        layer_Number {
            display-name = "NUM";
            bindings = <
   &none  &kp ENTER  &kp SPACE  &kp TAB  &kp BSPC  &kp N0     &none  &kp N7  &kp N8  &kp N9  &kp LS(SEMI)  &kp LS(N5)
   &sk LSHFT  &kp LCTRL  &kp LALT  &kp LGUI  &kp LSHFT  &kp X     &none  &kp N4  &kp N5  &kp N6  &kp MINUS  &kp LS(EQUAL)
   &kp E  &select_all  &select_line  &select_word  &kp _FIND  &kp F     &none  &kp N1  &kp N2  &kp N3  &kp FSLH  &kp LS(N8)
                     &none  &none  &tog LAYER_Number     &kp DOT  &kp N0  &kp EQUAL
            >;
        };

        /* Transport moved to W/E/R (Ret/Space/Tab there are redundant). Brightness
         * dropped -- macOS has its own keys. Next takes the T1 thumb, displacing
         * mute onto R.
         */
        layer_Function {
            display-name = "FUNC";
            bindings = <
   &none  &kp ENTER  &kp SPACE  &kp TAB  &kp BSPC  &none     &kp C_PREV  &kp F7  &kp F8  &kp F9  &kp F10  &kp F13
   &sk LSHFT  &kp LCTRL  &kp LALT  &kp LGUI  &kp LSHFT  &none     &kp C_NEXT  &kp F4  &kp F5  &kp F6  &kp F11  &kp F14
   &none  &select_all  &select_line  &select_word  &kp _FIND  &kp _FILES     &kp _FILES  &kp F1  &kp F2  &kp F3  &kp F12  &kp F15
                     &tog LAYER_Function  &none  &none     &kp C_VOL_DN  &kp C_VOL_UP  &kp C_PP
            >;
        };

        /* ( and ) had no surviving home -- every instance lived on R2/R6. Rehomed
         * onto the Shift-Tab / Insert keys (middle and ring, row above home),
         * which are redundant here. ( on ring and ) on middle preserves sunaku's
         * inward roll. & and @ take the equally-redundant Del and Esc.
         *
         * Right-hand same-hand mods rescued from R6 onto the home row, replacing
         * Bspc/Tab/Space/Ret -- all four already on thumbs. Better placed than the
         * Glove80 manages.
         */
        layer_Symbol {
            display-name = "SYM";
            bindings = <
   &kp LS(N1)  &kp LBKT  &kp LS(LBKT)  &kp LS(RBKT)  &kp RBKT  &kp LS(FSLH)     &kp DOT  &kp LS(N2)  &kp LPAR  &kp RPAR  &kp LS(N7)  &dot_dot
   &kp LS(N3)  &kp LS(N6)  &kp EQUAL  &kp LS(MINUS)  &kp LS(N4)  &kp LS(N8)     &kp COMMA  &kp BSPC  &kp TAB  &kp SPACE  &kp ENTER  &triple_backtick
   &kp LS(GRAVE)  &kp LS(COMMA)  &kp LS(BSLH)  &kp MINUS  &kp LS(DOT)  &kp FSLH     &kp SEMI  &kp LS(SQT)  &kp SQT  &kp GRAVE  &kp BSLH  &trans
                     &kp BSLH  &kp LS(N5)  &kp LS(SEMI)     &none  &tog LAYER_Symbol  &none
            >;
        };

        layer_Mouse {
            display-name = "MOUS";
            bindings = <
   &none  &none  &msc SCRL_LEFT  &mmv MOVE_UP  &msc SCRL_RIGHT  &none     &msc SCRL_LEFT  &mkp LCLK  &mkp MCLK  &mkp RCLK  &msc SCRL_RIGHT  &none
   &none  &msc SCRL_UP  &mmv MOVE_LEFT  &mmv MOVE_DOWN  &mmv MOVE_RIGHT  &msc SCRL_UP     &msc SCRL_UP  &mo LAYER_MouseFast  &mo LAYER_MouseWarp  &mo LAYER_MouseSlow  &kp K_APP  &mkp MB4
   &none  &msc SCRL_DOWN  &mo LAYER_MouseSlow  &mo LAYER_MouseWarp  &mo LAYER_MouseFast  &msc SCRL_DOWN     &msc SCRL_DOWN  &kp RSHFT  &kp RGUI  &kp LALT  &kp RCTRL  &mkp MB5
                     &mkp MB4  &mkp LCLK  &mkp RCLK     &tog LAYER_Mouse  &none  &kp _PASTE
            >;
        };

        layer_MouseSlow {
            display-name = "MSLO";
            bindings = <
   &trans  &trans  &trans  &trans  &trans  &trans     &trans  &trans  &trans  &trans  &trans  &trans
   &trans  &trans  &trans  &trans  &trans  &trans     &trans  &trans  &trans  &trans  &trans  &trans
   &trans  &trans  &trans  &trans  &trans  &trans     &trans  &trans  &trans  &trans  &trans  &trans
                     &trans  &trans  &trans           &trans  &trans  &trans
            >;
        };

        layer_MouseFast {
            display-name = "MFST";
            bindings = <
   &trans  &trans  &trans  &trans  &trans  &trans     &trans  &trans  &trans  &trans  &trans  &trans
   &trans  &trans  &trans  &trans  &trans  &trans     &trans  &trans  &trans  &trans  &trans  &trans
   &trans  &trans  &trans  &trans  &trans  &trans     &trans  &trans  &trans  &trans  &trans  &trans
                     &trans  &trans  &trans           &trans  &trans  &trans
            >;
        };

        layer_MouseWarp {
            display-name = "MWRP";
            bindings = <
   &trans  &trans  &trans  &trans  &trans  &trans     &trans  &trans  &trans  &trans  &trans  &trans
   &trans  &trans  &trans  &trans  &trans  &trans     &trans  &trans  &trans  &trans  &trans  &trans
   &trans  &trans  &trans  &trans  &trans  &trans     &trans  &trans  &trans  &trans  &trans  &trans
                     &trans  &trans  &trans           &trans  &trans  &trans
            >;
        };

        /* Rows 1-2 are 100% &rgb_ug on the Glove80. With no LEDs that is 20 free
         * keys, so the right-hand same-hand mods land on the home row here too.
         * _POWER sits on the outer pinky of row 1: reachable, hard to hit by
         * accident, and only live while the System thumb is held.
         */
        layer_System {
            display-name = "SYS";
            bindings = <
   &none  &none  &none  &none  &kp C_BRI_UP  &none     &none  &kp C_BRI_UP  &none  &none  &none  &none
   &none  &none  &none  &none  &kp C_BRI_DN  &none     &none  &kp C_BRI_DN  &none  &none  &kp _LOCK  &none
   &none  &none  &none  &kp LG(LS(N4))  &none  &none     &none  &kp RSHFT  &kp RGUI  &kp LALT  &kp RCTRL  &none
                     &kp _LOCK  &none  &none     &kp LG(LS(N5))  &kp LG(LS(N4))  &tog LAYER_System
            >;
        };


        /* Held from the outer pinky below "=". Bluetooth and bootloader live here;
         * without them a wireless board cannot be paired or reflashed. sunaku's
         * &to 0..3 alpha selectors are gone -- this build is QWERTY only.
         */
        layer_Magic {
            display-name = "MAGIC";
            bindings = <
     &bt BT_CLR        &bt_0         &bt_1         &bt_2         &bt_3  &none     &none  &none  &none  &none  &none      &bt BT_CLR_ALL
    &bootloader         &none         &none         &none         &none  &none     &none  &none  &none  &none  &none         &bootloader
     &sys_reset         &none         &none         &none  &tog LAYER_Typing  &none  &none  &none  &none  &none  &none        &sys_reset
                          &out OUT_USB  &out OUT_BLE  &none                &none  &none  &none
            >;
        };

    };
};
